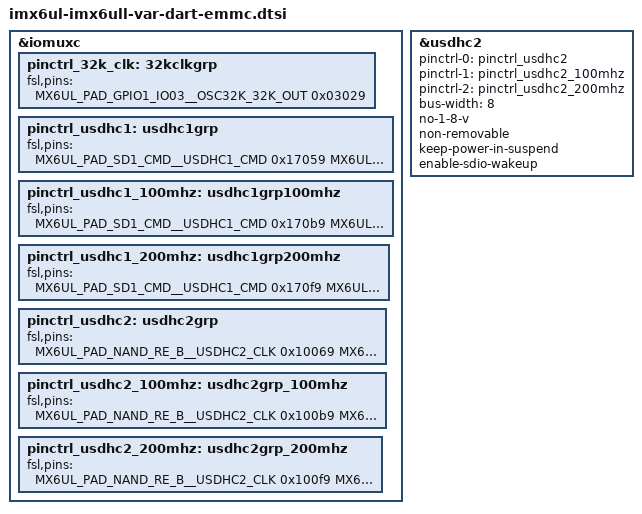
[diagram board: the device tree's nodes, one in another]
/*
 * Copyright (C) 2015-2025 Variscite Ltd. - https://www.variscite.com
 *
 * This program is free software; you can redistribute it and/or modify
 * it under the terms of the GNU General Public License version 2 as
 * published by the Free Software Foundation.
 */

&iomuxc {
	pinctrl_32k_clk: 32kclkgrp {
		fsl,pins = <
			MX6UL_PAD_GPIO1_IO03__OSC32K_32K_OUT	0x03029
		>;
	};

	pinctrl_usdhc1: usdhc1grp {
		fsl,pins = <
			MX6UL_PAD_SD1_CMD__USDHC1_CMD		0x17059
			MX6UL_PAD_SD1_CLK__USDHC1_CLK		0x17059
			MX6UL_PAD_SD1_DATA0__USDHC1_DATA0	0x17059
			MX6UL_PAD_SD1_DATA1__USDHC1_DATA1	0x17059
			MX6UL_PAD_SD1_DATA2__USDHC1_DATA2	0x17059
			MX6UL_PAD_SD1_DATA3__USDHC1_DATA3	0x17059
		>;
	};

	pinctrl_usdhc1_100mhz: usdhc1grp100mhz {
		fsl,pins = <
			MX6UL_PAD_SD1_CMD__USDHC1_CMD		0x170b9
			MX6UL_PAD_SD1_CLK__USDHC1_CLK		0x100b9
			MX6UL_PAD_SD1_DATA0__USDHC1_DATA0	0x170b9
			MX6UL_PAD_SD1_DATA1__USDHC1_DATA1	0x170b9
			MX6UL_PAD_SD1_DATA2__USDHC1_DATA2	0x170b9
			MX6UL_PAD_SD1_DATA3__USDHC1_DATA3	0x170b9
		>;
	};

	pinctrl_usdhc1_200mhz: usdhc1grp200mhz {
		fsl,pins = <
			MX6UL_PAD_SD1_CMD__USDHC1_CMD		0x170f9
			MX6UL_PAD_SD1_CLK__USDHC1_CLK		0x100f9
			MX6UL_PAD_SD1_DATA0__USDHC1_DATA0	0x170f9
			MX6UL_PAD_SD1_DATA1__USDHC1_DATA1	0x170f9
			MX6UL_PAD_SD1_DATA2__USDHC1_DATA2	0x170f9
			MX6UL_PAD_SD1_DATA3__USDHC1_DATA3	0x170f9
		>;
	};

	pinctrl_usdhc2: usdhc2grp {
		fsl,pins = <
			MX6UL_PAD_NAND_RE_B__USDHC2_CLK		0x10069
			MX6UL_PAD_NAND_WE_B__USDHC2_CMD		0x17059
			MX6UL_PAD_NAND_DATA00__USDHC2_DATA0	0x17059
			MX6UL_PAD_NAND_DATA01__USDHC2_DATA1	0x17059
			MX6UL_PAD_NAND_DATA02__USDHC2_DATA2	0x17059
			MX6UL_PAD_NAND_DATA03__USDHC2_DATA3	0x17059
			MX6UL_PAD_NAND_DATA04__USDHC2_DATA4	0x17059
			MX6UL_PAD_NAND_DATA05__USDHC2_DATA5	0x17059
			MX6UL_PAD_NAND_DATA06__USDHC2_DATA6	0x17059
			MX6UL_PAD_NAND_DATA07__USDHC2_DATA7	0x17059
		>;
	};

	pinctrl_usdhc2_100mhz: usdhc2grp_100mhz {
		fsl,pins = <
			MX6UL_PAD_NAND_RE_B__USDHC2_CLK		0x100b9
			MX6UL_PAD_NAND_WE_B__USDHC2_CMD		0x170b9
			MX6UL_PAD_NAND_DATA00__USDHC2_DATA0	0x170b9
			MX6UL_PAD_NAND_DATA01__USDHC2_DATA1	0x170b9
			MX6UL_PAD_NAND_DATA02__USDHC2_DATA2	0x170b9
			MX6UL_PAD_NAND_DATA03__USDHC2_DATA3	0x170b9
			MX6UL_PAD_NAND_DATA04__USDHC2_DATA4	0x170b9
			MX6UL_PAD_NAND_DATA05__USDHC2_DATA5	0x170b9
			MX6UL_PAD_NAND_DATA06__USDHC2_DATA6	0x170b9
			MX6UL_PAD_NAND_DATA07__USDHC2_DATA7	0x170b9
		>;
	};

	pinctrl_usdhc2_200mhz: usdhc2grp_200mhz {
		fsl,pins = <
			MX6UL_PAD_NAND_RE_B__USDHC2_CLK		0x100f9
			MX6UL_PAD_NAND_WE_B__USDHC2_CMD		0x170f9
			MX6UL_PAD_NAND_DATA00__USDHC2_DATA0	0x170f9
			MX6UL_PAD_NAND_DATA01__USDHC2_DATA1	0x170f9
			MX6UL_PAD_NAND_DATA02__USDHC2_DATA2	0x170f9
			MX6UL_PAD_NAND_DATA03__USDHC2_DATA3	0x170f9
			MX6UL_PAD_NAND_DATA04__USDHC2_DATA4	0x170f9
			MX6UL_PAD_NAND_DATA05__USDHC2_DATA5	0x170f9
			MX6UL_PAD_NAND_DATA06__USDHC2_DATA6	0x170f9
			MX6UL_PAD_NAND_DATA07__USDHC2_DATA7	0x170f9
		>;
	};
};

&usdhc2 {
	pinctrl-names = "default", "state_100mhz", "state_200mhz";
	pinctrl-0 = <&pinctrl_usdhc2>;
	pinctrl-1 = <&pinctrl_usdhc2_100mhz>;
	pinctrl-2 = <&pinctrl_usdhc2_200mhz>;
	bus-width = <8>;
	no-1-8-v;
	non-removable;
	keep-power-in-suspend;
	enable-sdio-wakeup;
	status = "okay";
};
